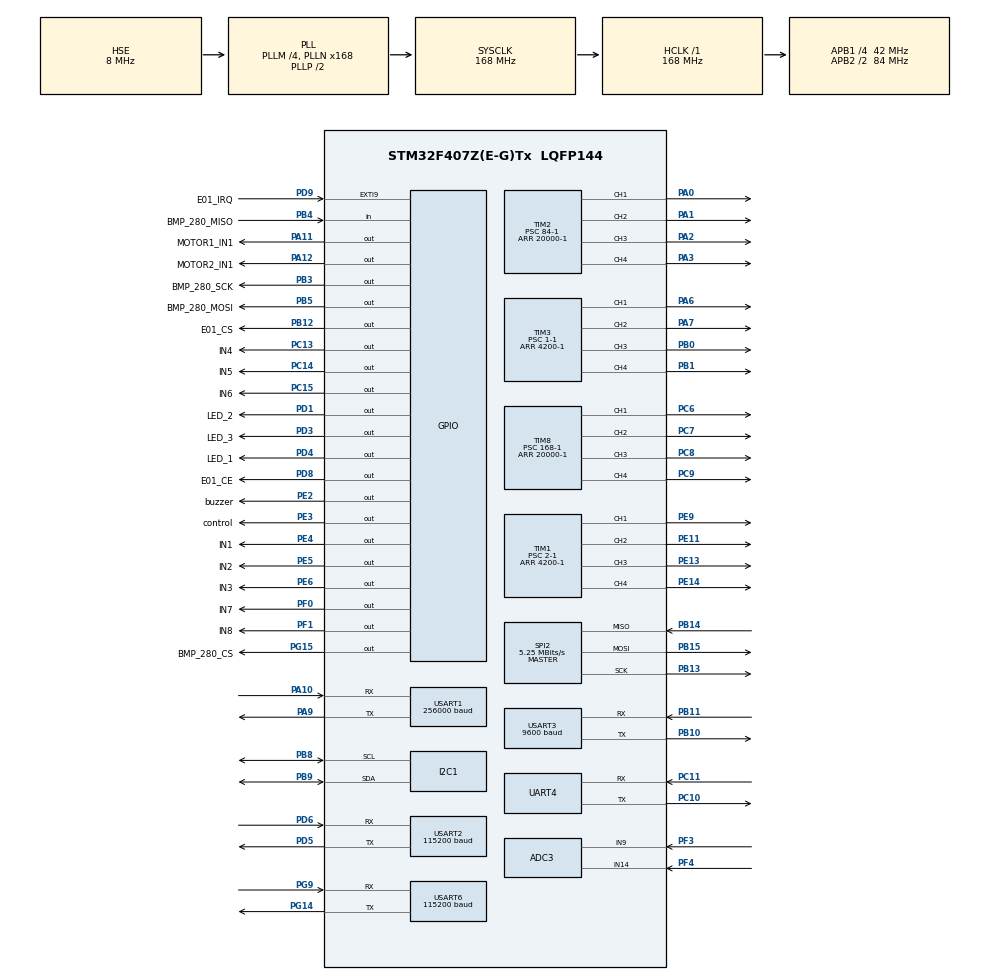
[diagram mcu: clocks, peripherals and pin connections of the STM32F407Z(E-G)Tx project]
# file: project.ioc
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ADC3.Channel-0\#ChannelRegularConversion=ADC_CHANNEL_14
ADC3.Channel-1\#ChannelRegularConversion=ADC_CHANNEL_9
ADC3.ClockPrescaler=ADC_CLOCK_SYNC_PCLK_DIV4
ADC3.ContinuousConvMode=DISABLE
ADC3.DiscontinuousConvMode=DISABLE
ADC3.EOCSelection=ADC_EOC_SEQ_CONV
ADC3.NbrOfConversion=2
ADC3.NbrOfConversionFlag=1
ADC3.Rank-0\#ChannelRegularConversion=1
ADC3.Rank-1\#ChannelRegularConversion=2
ADC3.SamplingTime-0\#ChannelRegularConversion=ADC_SAMPLETIME_480CYCLES
ADC3.SamplingTime-1\#ChannelRegularConversion=ADC_SAMPLETIME_480CYCLES
Dma.ADC3.8.Direction=DMA_PERIPH_TO_MEMORY
Dma.ADC3.8.FIFOMode=DMA_FIFOMODE_DISABLE
Dma.ADC3.8.Instance=DMA2_Stream0
Dma.ADC3.8.MemDataAlignment=DMA_MDATAALIGN_HALFWORD
Dma.ADC3.8.MemInc=DMA_MINC_ENABLE
Dma.ADC3.8.Mode=DMA_CIRCULAR
Dma.ADC3.8.PeriphDataAlignment=DMA_PDATAALIGN_HALFWORD
Dma.ADC3.8.PeriphInc=DMA_PINC_DISABLE
Dma.ADC3.8.Priority=DMA_PRIORITY_LOW
Dma.Request0=USART1_TX
Dma.Request1=USART1_RX
Dma.Request2=USART2_TX
Dma.Request3=USART2_RX
Dma.Request4=USART3_TX
Dma.Request5=USART3_RX
Dma.Request6=USART6_RX
Dma.Request7=UART4_RX
Dma.Request8=ADC3
Dma.UART4_RX.7.Direction=DMA_PERIPH_TO_MEMORY
Dma.UART4_RX.7.FIFOMode=DMA_FIFOMODE_DISABLE
Dma.UART4_RX.7.Instance=DMA1_Stream2
Dma.UART4_RX.7.MemDataAlignment=DMA_MDATAALIGN_BYTE
Dma.UART4_RX.7.MemInc=DMA_MINC_ENABLE
Dma.UART4_RX.7.Mode=DMA_NORMAL
Dma.UART4_RX.7.PeriphDataAlignment=DMA_PDATAALIGN_BYTE
Dma.UART4_RX.7.PeriphInc=DMA_PINC_DISABLE
Dma.UART4_RX.7.Priority=DMA_PRIORITY_LOW
Dma.USART1_RX.1.Direction=DMA_PERIPH_TO_MEMORY
Dma.USART1_RX.1.FIFOMode=DMA_FIFOMODE_DISABLE
Dma.USART1_RX.1.Instance=DMA2_Stream2
Dma.USART1_RX.1.MemDataAlignment=DMA_MDATAALIGN_BYTE
Dma.USART1_RX.1.MemInc=DMA_MINC_ENABLE
Dma.USART1_RX.1.Mode=DMA_NORMAL
Dma.USART1_RX.1.PeriphDataAlignment=DMA_PDATAALIGN_BYTE
Dma.USART1_RX.1.PeriphInc=DMA_PINC_DISABLE
Dma.USART1_RX.1.Priority=DMA_PRIORITY_LOW
Dma.USART1_TX.0.Direction=DMA_MEMORY_TO_PERIPH
Dma.USART1_TX.0.FIFOMode=DMA_FIFOMODE_DISABLE
Dma.USART1_TX.0.Instance=DMA2_Stream7
Dma.USART1_TX.0.MemDataAlignment=DMA_MDATAALIGN_BYTE
Dma.USART1_TX.0.MemInc=DMA_MINC_ENABLE
Dma.USART1_TX.0.Mode=DMA_NORMAL
Dma.USART1_TX.0.PeriphDataAlignment=DMA_PDATAALIGN_BYTE
Dma.USART1_TX.0.PeriphInc=DMA_PINC_DISABLE
Dma.USART1_TX.0.Priority=DMA_PRIORITY_LOW
Dma.USART2_RX.3.Direction=DMA_PERIPH_TO_MEMORY
Dma.USART2_RX.3.FIFOMode=DMA_FIFOMODE_DISABLE
Dma.USART2_RX.3.Instance=DMA1_Stream5
Dma.USART2_RX.3.MemDataAlignment=DMA_MDATAALIGN_BYTE
Dma.USART2_RX.3.MemInc=DMA_MINC_ENABLE
Dma.USART2_RX.3.Mode=DMA_NORMAL
Dma.USART2_RX.3.PeriphDataAlignment=DMA_PDATAALIGN_BYTE
Dma.USART2_RX.3.PeriphInc=DMA_PINC_DISABLE
Dma.USART2_RX.3.Priority=DMA_PRIORITY_LOW
Dma.USART2_TX.2.Direction=DMA_MEMORY_TO_PERIPH
Dma.USART2_TX.2.FIFOMode=DMA_FIFOMODE_DISABLE
Dma.USART2_TX.2.Instance=DMA1_Stream6
Dma.USART2_TX.2.MemDataAlignment=DMA_MDATAALIGN_BYTE
Dma.USART2_TX.2.MemInc=DMA_MINC_ENABLE
Dma.USART2_TX.2.Mode=DMA_NORMAL
Dma.USART2_TX.2.PeriphDataAlignment=DMA_PDATAALIGN_BYTE
Dma.USART2_TX.2.PeriphInc=DMA_PINC_DISABLE
Dma.USART2_TX.2.Priority=DMA_PRIORITY_LOW
Dma.USART3_RX.5.Direction=DMA_PERIPH_TO_MEMORY
Dma.USART3_RX.5.FIFOMode=DMA_FIFOMODE_DISABLE
Dma.USART3_RX.5.Instance=DMA1_Stream1
Dma.USART3_RX.5.MemDataAlignment=DMA_MDATAALIGN_BYTE
Dma.USART3_RX.5.MemInc=DMA_MINC_ENABLE
Dma.USART3_RX.5.Mode=DMA_NORMAL
Dma.USART3_RX.5.PeriphDataAlignment=DMA_PDATAALIGN_BYTE
Dma.USART3_RX.5.PeriphInc=DMA_PINC_DISABLE
Dma.USART3_RX.5.Priority=DMA_PRIORITY_LOW
Dma.USART3_TX.4.Direction=DMA_MEMORY_TO_PERIPH
Dma.USART3_TX.4.FIFOMode=DMA_FIFOMODE_DISABLE
Dma.USART3_TX.4.Instance=DMA1_Stream3
Dma.USART3_TX.4.MemDataAlignment=DMA_MDATAALIGN_BYTE
Dma.USART3_TX.4.MemInc=DMA_MINC_ENABLE
Dma.USART3_TX.4.Mode=DMA_NORMAL
Dma.USART3_TX.4.PeriphDataAlignment=DMA_PDATAALIGN_BYTE
Dma.USART3_TX.4.PeriphInc=DMA_PINC_DISABLE
Dma.USART3_TX.4.Priority=DMA_PRIORITY_LOW
Dma.USART6_RX.6.Direction=DMA_PERIPH_TO_MEMORY
Dma.USART6_RX.6.FIFOMode=DMA_FIFOMODE_DISABLE
Dma.USART6_RX.6.Instance=DMA2_Stream1
Dma.USART6_RX.6.MemDataAlignment=DMA_MDATAALIGN_BYTE
Dma.USART6_RX.6.MemInc=DMA_MINC_ENABLE
Dma.USART6_RX.6.Mode=DMA_NORMAL
Dma.USART6_RX.6.PeriphDataAlignment=DMA_PDATAALIGN_BYTE
Dma.USART6_RX.6.PeriphInc=DMA_PINC_DISABLE
Dma.USART6_RX.6.Priority=DMA_PRIORITY_LOW
FREERTOS.INCLUDE_vTaskDelayUntil=1
FREERTOS.Tasks01=defaultTask,8,128,StartDefaultTask,Default,NULL,Dynamic,NULL,NULL
FREERTOS.configENABLE_FPU=1
FREERTOS.configUSE_COUNTING_SEMAPHORES=1
Mcu.Family=STM32F4
Mcu.Name=STM32F407Z(E-G)Tx
Mcu.Package=LQFP144
NVIC.DMA1_Stream1_IRQn=true\:5\:0\:false\:false\:true\:true\:false\:true\:true
NVIC.DMA1_Stream2_IRQn=true\:5\:0\:false\:false\:true\:true\:false\:true\:true
NVIC.DMA1_Stream3_IRQn=true\:5\:0\:false\:false\:true\:true\:false\:true\:true
NVIC.DMA1_Stream5_IRQn=true\:5\:0\:false\:false\:true\:true\:false\:true\:true
NVIC.DMA1_Stream6_IRQn=true\:5\:0\:false\:false\:true\:true\:false\:true\:true
NVIC.DMA2_Stream0_IRQn=true\:5\:0\:false\:false\:true\:true\:false\:true\:true
NVIC.DMA2_Stream1_IRQn=true\:5\:0\:false\:false\:true\:true\:false\:true\:true
NVIC.DMA2_Stream2_IRQn=true\:5\:0\:false\:false\:true\:true\:false\:true\:true
NVIC.DMA2_Stream7_IRQn=true\:5\:0\:false\:false\:true\:true\:false\:true\:true
NVIC.EXTI9_5_IRQn=true\:5\:0\:false\:false\:true\:true\:true\:true\:true
NVIC.PriorityGroup=NVIC_PRIORITYGROUP_4
NVIC.TIM6_DAC_IRQn=true\:5\:0\:false\:false\:true\:true\:true\:true\:true
NVIC.TIM7_IRQn=true\:15\:0\:false\:false\:true\:false\:false\:true\:true
NVIC.TimeBase=TIM7_IRQn
NVIC.TimeBaseIP=TIM7
NVIC.UART4_IRQn=true\:5\:0\:false\:false\:true\:true\:true\:true\:true
NVIC.USART1_IRQn=true\:5\:0\:false\:false\:true\:true\:true\:true\:true
NVIC.USART2_IRQn=true\:5\:0\:false\:false\:true\:true\:true\:true\:true
NVIC.USART3_IRQn=true\:5\:0\:false\:false\:true\:true\:true\:true\:true
NVIC.USART6_IRQn=true\:5\:0\:false\:false\:true\:true\:true\:true\:true
PA0-WKUP.Signal=S_TIM2_CH1_ETR
PA1.Signal=S_TIM2_CH2
PA10.Mode=Asynchronous
PA10.Signal=USART1_RX
PA11.GPIO_Label=MOTOR1_IN1
PA11.GPIO_ModeDefaultOutputPP=GPIO_MODE_OUTPUT_OD
PA11.GPIO_PuPd=GPIO_NOPULL
PA11.Signal=GPIO_Output
PA12.GPIO_Label=MOTOR2_IN1
PA12.GPIO_ModeDefaultOutputPP=GPIO_MODE_OUTPUT_OD
PA12.GPIO_PuPd=GPIO_NOPULL
PA12.Signal=GPIO_Output
PA13.Mode=Serial_Wire
PA13.Signal=SYS_JTMS-SWDIO
PA14.Mode=Serial_Wire
PA14.Signal=SYS_JTCK-SWCLK
PA2.Signal=S_TIM2_CH3
PA3.Signal=S_TIM2_CH4
PA6.Signal=S_TIM3_CH1
PA7.Signal=S_TIM3_CH2
PA9.Mode=Asynchronous
PA9.Signal=USART1_TX
PB0.Signal=S_TIM3_CH3
PB1.Signal=S_TIM3_CH4
PB10.Mode=Asynchronous
PB10.Signal=USART3_TX
PB11.Mode=Asynchronous
PB11.Signal=USART3_RX
PB12.GPIO_Label=E01_CS
PB12.GPIO_Speed=GPIO_SPEED_FREQ_VERY_HIGH
PB12.PinState=GPIO_PIN_SET
PB12.Signal=GPIO_Output
PB13.Mode=Full_Duplex_Master
PB13.Signal=SPI2_SCK
PB14.Mode=Full_Duplex_Master
PB14.Signal=SPI2_MISO
PB15.Mode=Full_Duplex_Master
PB15.Signal=SPI2_MOSI
PB3.GPIO_Label=BMP_280_SCK
PB3.GPIO_ModeDefaultOutputPP=GPIO_MODE_OUTPUT_PP
PB3.GPIO_PuPd=GPIO_NOPULL
PB3.GPIO_Speed=GPIO_SPEED_FREQ_VERY_HIGH
PB3.PinState=GPIO_PIN_RESET
PB3.Signal=GPIO_Output
PB4.GPIO_Label=BMP_280_MISO
PB4.GPIO_PuPd=GPIO_NOPULL
PB4.Signal=GPIO_Input
PB5.GPIO_Label=BMP_280_MOSI
PB5.GPIO_Speed=GPIO_SPEED_FREQ_VERY_HIGH
PB5.Signal=GPIO_Output
PB8.Mode=I2C
PB8.Signal=I2C1_SCL
PB9.Mode=I2C
PB9.Signal=I2C1_SDA
PC10.Mode=Asynchronous
PC10.Signal=UART4_TX
PC11.Mode=Asynchronous
PC11.Signal=UART4_RX
PC13-ANTI_TAMP.GPIO_Label=IN4
PC13-ANTI_TAMP.Signal=GPIO_Output
PC14-OSC32_IN.GPIO_Label=IN5
PC14-OSC32_IN.Signal=GPIO_Output
PC15-OSC32_OUT.GPIO_Label=IN6
PC15-OSC32_OUT.Signal=GPIO_Output
PC6.Signal=S_TIM8_CH1
PC7.Signal=S_TIM8_CH2
PC8.Signal=S_TIM8_CH3
PC9.Signal=S_TIM8_CH4
PD1.GPIO_Label=LED_2
PD1.PinState=GPIO_PIN_SET
PD1.Signal=GPIO_Output
PD3.GPIO_Label=LED_3
PD3.PinState=GPIO_PIN_SET
PD3.Signal=GPIO_Output
PD4.GPIO_Label=LED_1
PD4.PinState=GPIO_PIN_SET
PD4.Signal=GPIO_Output
PD5.Mode=Asynchronous
PD5.Signal=USART2_TX
PD6.Mode=Asynchronous
PD6.Signal=USART2_RX
PD8.GPIO_Label=E01_CE
PD8.Signal=GPIO_Output
PD9.GPIO_Label=E01_IRQ
PD9.GPIO_ModeDefaultEXTI=GPIO_MODE_IT_FALLING
PD9.GPIO_PuPd=GPIO_PULLUP
PD9.Signal=GPXTI9
PE11.Signal=S_TIM1_CH2
PE13.Signal=S_TIM1_CH3
PE14.Signal=S_TIM1_CH4
PE2.GPIO_Label=buzzer
PE2.Signal=GPIO_Output
PE3.GPIO_Label=control
PE3.Signal=GPIO_Output
PE4.GPIO_Label=IN1
PE4.Signal=GPIO_Output
PE5.GPIO_Label=IN2
PE5.Signal=GPIO_Output
PE6.GPIO_Label=IN3
PE6.Signal=GPIO_Output
PE9.Signal=S_TIM1_CH1
PF0.GPIO_Label=IN7
PF0.Signal=GPIO_Output
PF1.GPIO_Label=IN8
PF1.Signal=GPIO_Output
PF3.Mode=IN9
PF3.Signal=ADC3_IN9
PF4.Mode=IN14
PF4.Signal=ADC3_IN14
PG14.Mode=Asynchronous
PG14.Signal=USART6_TX
PG15.GPIO_Label=BMP_280_CS
PG15.GPIO_Speed=GPIO_SPEED_FREQ_VERY_HIGH
PG15.PinState=GPIO_PIN_SET
PG15.Signal=GPIO_Output
PG9.Mode=Asynchronous
PG9.Signal=USART6_RX
PH0-OSC_IN.Mode=HSE-External-Oscillator
PH0-OSC_IN.Signal=RCC_OSC_IN
PH1-OSC_OUT.Mode=HSE-External-Oscillator
PH1-OSC_OUT.Signal=RCC_OSC_OUT
ProjectManager.HeapSize=0x200
ProjectManager.StackSize=0x400
ProjectManager.TargetToolchain=MDK-ARM V5.32
RCC.48MHZClocksFreq_Value=84000000
RCC.AHBFreq_Value=168000000
RCC.APB1CLKDivider=RCC_HCLK_DIV4
RCC.APB1Freq_Value=42000000
RCC.APB1TimFreq_Value=84000000
RCC.APB2CLKDivider=RCC_HCLK_DIV2
RCC.APB2Freq_Value=84000000
RCC.APB2TimFreq_Value=168000000
RCC.CortexFreq_Value=168000000
RCC.HCLKFreq_Value=168000000
RCC.HSE_VALUE=8000000
RCC.HSI_VALUE=16000000
RCC.LSE_VALUE=32768
RCC.PLLM=4
RCC.PLLN=168
RCC.PLLSourceVirtual=RCC_PLLSOURCE_HSE
RCC.SYSCLKFreq_VALUE=168000000
RCC.SYSCLKSource=RCC_SYSCLKSOURCE_PLLCLK
RCC.VCOOutputFreq_Value=336000000
SH.S_TIM1_CH1.0=TIM1_CH1,PWM Generation1 CH1
SH.S_TIM1_CH2.0=TIM1_CH2,PWM Generation2 CH2
SH.S_TIM1_CH3.0=TIM1_CH3,PWM Generation3 CH3
SH.S_TIM1_CH4.0=TIM1_CH4,PWM Generation4 CH4
SH.S_TIM2_CH1_ETR.0=TIM2_CH1,PWM Generation1 CH1
SH.S_TIM2_CH2.0=TIM2_CH2,PWM Generation2 CH2
SH.S_TIM2_CH3.0=TIM2_CH3,PWM Generation3 CH3
SH.S_TIM2_CH4.0=TIM2_CH4,PWM Generation4 CH4
SH.S_TIM3_CH1.0=TIM3_CH1,PWM Generation1 CH1
SH.S_TIM3_CH2.0=TIM3_CH2,PWM Generation2 CH2
SH.S_TIM3_CH3.0=TIM3_CH3,PWM Generation3 CH3
SH.S_TIM3_CH4.0=TIM3_CH4,PWM Generation4 CH4
SH.S_TIM8_CH1.0=TIM8_CH1,PWM Generation1 CH1
SH.S_TIM8_CH2.0=TIM8_CH2,PWM Generation2 CH2
SH.S_TIM8_CH3.0=TIM8_CH3,PWM Generation3 CH3
SH.S_TIM8_CH4.0=TIM8_CH4,PWM Generation4 CH4
SPI2.BaudRatePrescaler=SPI_BAUDRATEPRESCALER_8
SPI2.CalculateBaudRate=5.25 MBits/s
SPI2.Direction=SPI_DIRECTION_2LINES
SPI2.Mode=SPI_MODE_MASTER
SPI2.VirtualType=VM_MASTER
STMicroelectronics.X-CUBE-ALGOBUILD.1.3.0.LibraryCcDSPOoLibraryJjDSPOoLibrary=true
TIM1.Channel-Output\ Compare2\ CH2=TIM_CHANNEL_2
TIM1.Channel-Output\ Compare3\ CH3=TIM_CHANNEL_3
TIM1.Channel-Output\ Compare4\ CH4=TIM_CHANNEL_4
TIM1.Channel-PWM\ Generation1\ CH1=TIM_CHANNEL_1
TIM1.Channel-PWM\ Generation2\ CH2=TIM_CHANNEL_2
TIM1.Channel-PWM\ Generation3\ CH3=TIM_CHANNEL_3
TIM1.Channel-PWM\ Generation4\ CH4=TIM_CHANNEL_4
TIM1.Period=4200-1
TIM1.Prescaler=2-1
TIM2.Channel-PWM\ Generation1\ CH1=TIM_CHANNEL_1
TIM2.Channel-PWM\ Generation2\ CH2=TIM_CHANNEL_2
TIM2.Channel-PWM\ Generation3\ CH3=TIM_CHANNEL_3
TIM2.Channel-PWM\ Generation4\ CH4=TIM_CHANNEL_4
TIM2.Period=20000-1
TIM2.Prescaler=84-1
TIM3.Channel-PWM\ Generation1\ CH1=TIM_CHANNEL_1
TIM3.Channel-PWM\ Generation2\ CH2=TIM_CHANNEL_2
TIM3.Channel-PWM\ Generation3\ CH3=TIM_CHANNEL_3
TIM3.Channel-PWM\ Generation4\ CH4=TIM_CHANNEL_4
TIM3.Period=4200-1
TIM3.Prescaler=1-1
TIM6.Period=10-1
TIM6.Prescaler=8400-1
TIM8.Channel-PWM\ Generation1\ CH1=TIM_CHANNEL_1
TIM8.Channel-PWM\ Generation2\ CH2=TIM_CHANNEL_2
TIM8.Channel-PWM\ Generation3\ CH3=TIM_CHANNEL_3
TIM8.Channel-PWM\ Generation4\ CH4=TIM_CHANNEL_4
TIM8.Period=20000-1
TIM8.Prescaler=168-1
UART4.VirtualMode=Asynchronous
USART1.BaudRate=256000
USART1.VirtualMode=VM_ASYNC
USART2.BaudRate=115200
USART2.VirtualMode=VM_ASYNC
USART3.BaudRate=9600
USART3.VirtualMode=VM_ASYNC
USART6.BaudRate=115200
USART6.VirtualMode=VM_ASYNC
VP_FREERTOS_VS_CMSIS_V2.Mode=CMSIS_V2
VP_STMicroelectronics.X-CUBE-ALGOBUILD_VS_DSPOoLibraryJjLibrary_1.3.0_1.3.0.Mode=DSPOoLibraryJjLibrary
VP_SYS_VS_tim7.Mode=TIM7
VP_TIM1_VS_ClockSourceINT.Mode=Internal
VP_TIM2_VS_ClockSourceINT.Mode=Internal
VP_TIM3_VS_ClockSourceINT.Mode=Internal
VP_TIM6_VS_ClockSourceINT.Mode=Enable_Timer
VP_TIM8_VS_ClockSourceINT.Mode=Internal
board=custom

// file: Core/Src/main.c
/* USER CODE BEGIN Header */
/**
  ******************************************************************************
  * @file           : main.c
  * @brief          : Main program body
  ******************************************************************************
  * @attention
  *
  * Copyright (c) 2025 STMicroelectronics.
  * All rights reserved.
  *
  * This software is licensed under terms that can be found in the LICENSE file
  * in the root directory of this software component.
  * If no LICENSE file comes with this software, it is provided AS-IS.
  *
  ******************************************************************************
  */
/* USER CODE END Header */
#include "main.h"
#include "cmsis_os.h"
#include "adc.h"
#include "dma.h"
#include "i2c.h"
#include "spi.h"
#include "tim.h"
#include "usart.h"
#include "gpio.h"

/* USER CODE BEGIN Includes */
#include "app_init.h"
#include "globalTime.h"
/* USER CODE END Includes */

void SystemClock_Config(void);
void MX_FREERTOS_Init(void);

int main(void)
{

  /* MCU Configuration--------------------------------------------------------*/

  /* Reset of all peripherals, Initializes the Flash interface and the Systick. */
  HAL_Init();

  /* Configure the system clock */
  SystemClock_Config();

  /* USER CODE BEGIN SysInit */
	// 提前将电调信号引脚 PC6-PC9 拉低，避免浮空期 EMI 干扰电调初始化
	__HAL_RCC_GPIOC_CLK_ENABLE();
	HAL_GPIO_WritePin(GPIOC, GPIO_PIN_6|GPIO_PIN_7|GPIO_PIN_8|GPIO_PIN_9, GPIO_PIN_RESET);
	GPIO_InitTypeDef esc_gpio = {0};
	esc_gpio.Pin = GPIO_PIN_6|GPIO_PIN_7|GPIO_PIN_8|GPIO_PIN_9;
	esc_gpio.Mode = GPIO_MODE_OUTPUT_PP;
	esc_gpio.Pull = GPIO_NOPULL;
	esc_gpio.Speed = GPIO_SPEED_FREQ_LOW;
	HAL_GPIO_Init(GPIOC, &esc_gpio);
	HAL_Delay(300);
  /* USER CODE END SysInit */

  /* Initialize all configured peripherals */
  MX_GPIO_Init();
  MX_DMA_Init();
  MX_I2C1_Init();
  MX_SPI2_Init();
  MX_TIM2_Init();
  MX_TIM3_Init();
  MX_TIM8_Init();
  MX_UART4_Init();
  MX_USART2_UART_Init();
  MX_USART3_UART_Init();
  MX_USART6_UART_Init();
  MX_USART1_UART_Init();
  MX_ADC3_Init();
  MX_TIM6_Init();
  MX_TIM1_Init();
  /* USER CODE BEGIN 2 */
  xTaskCreate(App_InitTask,"Init",250,NULL,20,NULL);
  /* USER CODE END 2 */

  /* Init scheduler */
  osKernelInitialize();

  /* Call init function for freertos objects (in cmsis_os2.c) */
  MX_FREERTOS_Init();

  /* Start scheduler */
  osKernelStart();

  /* We should never get here as control is now taken by the scheduler */

  /* Infinite loop */
  /* USER CODE BEGIN WHILE */
  while (1)
  {
	// TIM6_pollCall(getGlobalTime());
    /* USER CODE END WHILE */

  }
}

void SystemClock_Config(void)
{
  RCC_OscInitTypeDef RCC_OscInitStruct = {0};
  RCC_ClkInitTypeDef RCC_ClkInitStruct = {0};

  /** Configure the main internal regulator output voltage
  */
  __HAL_RCC_PWR_CLK_ENABLE();
  __HAL_PWR_VOLTAGESCALING_CONFIG(PWR_REGULATOR_VOLTAGE_SCALE1);

  /** Initializes the RCC Oscillators according to the specified parameters
  * in the RCC_OscInitTypeDef structure.
  */
  RCC_OscInitStruct.OscillatorType = RCC_OSCILLATORTYPE_HSE;
  RCC_OscInitStruct.HSEState = RCC_HSE_ON;
  RCC_OscInitStruct.PLL.PLLState = RCC_PLL_ON;
  RCC_OscInitStruct.PLL.PLLSource = RCC_PLLSOURCE_HSE;
  RCC_OscInitStruct.PLL.PLLM = 4;
  RCC_OscInitStruct.PLL.PLLN = 168;
  RCC_OscInitStruct.PLL.PLLP = RCC_PLLP_DIV2;
  RCC_OscInitStruct.PLL.PLLQ = 4;
  if (HAL_RCC_OscConfig(&RCC_OscInitStruct) != HAL_OK)
  {
    Error_Handler();
  }

  /** Initializes the CPU, AHB and APB buses clocks
  */
  RCC_ClkInitStruct.ClockType = RCC_CLOCKTYPE_HCLK|RCC_CLOCKTYPE_SYSCLK
                              |RCC_CLOCKTYPE_PCLK1|RCC_CLOCKTYPE_PCLK2;
  RCC_ClkInitStruct.SYSCLKSource = RCC_SYSCLKSOURCE_PLLCLK;
  RCC_ClkInitStruct.AHBCLKDivider = RCC_SYSCLK_DIV1;
  RCC_ClkInitStruct.APB1CLKDivider = RCC_HCLK_DIV4;
  RCC_ClkInitStruct.APB2CLKDivider = RCC_HCLK_DIV2;

  if (HAL_RCC_ClockConfig(&RCC_ClkInitStruct, FLASH_LATENCY_5) != HAL_OK)
  {
    Error_Handler();
  }
}

void HAL_TIM_PeriodElapsedCallback(TIM_HandleTypeDef *htim)
{
  /* USER CODE BEGIN Callback 0 */
  globalTimeCallBack(htim);
  /* USER CODE END Callback 0 */
  if (htim->Instance == TIM7) {
    HAL_IncTick();
  }
}

void Error_Handler(void)
{
  __disable_irq();
  while (1)
  {
  }
}
